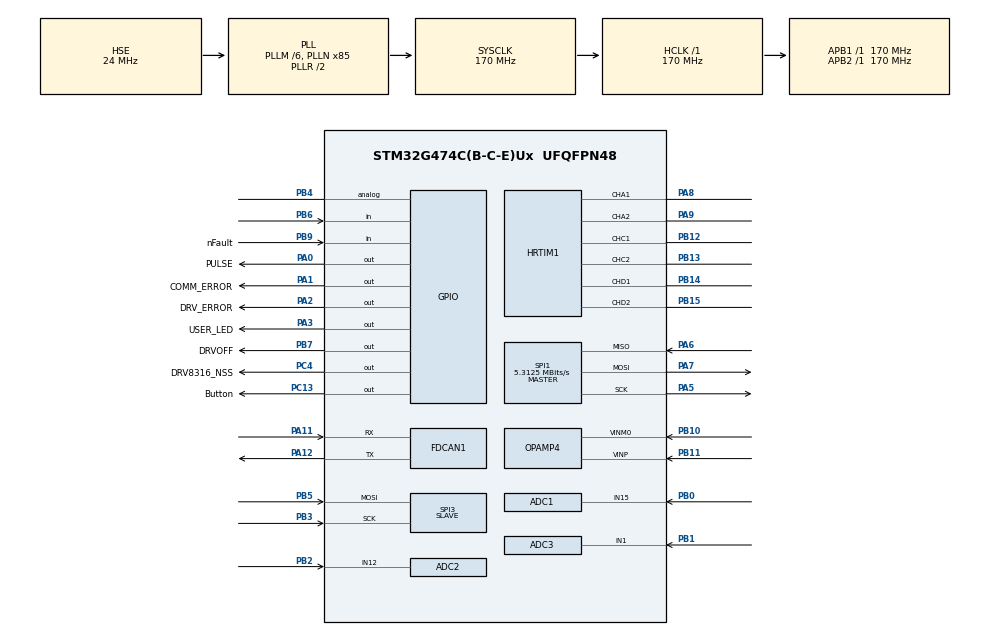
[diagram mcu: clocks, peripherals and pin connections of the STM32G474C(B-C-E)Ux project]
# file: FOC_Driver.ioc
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ADC1.DMAContinuousRequests=DISABLE
ADC1.EnableInjectedConversion=ENABLE
ADC1.EnableInjectedOversampling=DISABLE
ADC1.EnableRegularConversion=DISABLE
ADC1.ExternalTrigInjecConv=ADC_EXTERNALTRIGINJEC_HRTIM_TRG2
ADC1.InjNumberOfConversion=1
ADC1.InjectedChannel-18\#ChannelInjectedConversion=ADC_CHANNEL_15
ADC1.InjectedConvMode=None
ADC1.InjectedOffsetNumber-18\#ChannelInjectedConversion=ADC_OFFSET_NONE
ADC1.InjectedRank-18\#ChannelInjectedConversion=1
ADC1.InjectedSamplingTime-18\#ChannelInjectedConversion=ADC_SAMPLETIME_24CYCLES_5
ADC1.Overrun=ADC_OVR_DATA_OVERWRITTEN
ADC1.injectedQueueMode=DISABLE
ADC1.master=1
ADC2.ClockPrescaler=ADC_CLOCK_SYNC_PCLK_DIV4
ADC2.ContinuousConvMode=DISABLE
ADC2.DMAContinuousRequests=DISABLE
ADC2.EnableInjectedConversion=ENABLE
ADC2.EnableInjectedOversampling=DISABLE
ADC2.EnableRegularConversion=DISABLE
ADC2.ExternalTrigInjecConv=ADC_EXTERNALTRIGINJEC_HRTIM_TRG2
ADC2.InjNumberOfConversion=1
ADC2.InjectedChannel-6\#ChannelInjectedConversion=ADC_CHANNEL_12
ADC2.InjectedOffsetNumber-6\#ChannelInjectedConversion=ADC_OFFSET_NONE
ADC2.InjectedRank-6\#ChannelInjectedConversion=1
ADC2.InjectedSamplingTime-6\#ChannelInjectedConversion=ADC_SAMPLETIME_24CYCLES_5
ADC2.Overrun=ADC_OVR_DATA_OVERWRITTEN
ADC2.OversamplingMode=DISABLE
ADC3.DMAContinuousRequests=DISABLE
ADC3.EnableInjectedConversion=ENABLE
ADC3.EnableInjectedOversampling=DISABLE
ADC3.EnableRegularConversion=DISABLE
ADC3.ExternalTrigInjecConv=ADC_EXTERNALTRIGINJEC_HRTIM_TRG2
ADC3.InjNumberOfConversion=1
ADC3.InjectedChannel-5\#ChannelInjectedConversion=ADC_CHANNEL_1
ADC3.InjectedOffsetNumber-5\#ChannelInjectedConversion=ADC_OFFSET_NONE
ADC3.InjectedRank-5\#ChannelInjectedConversion=1
ADC3.InjectedSamplingTime-5\#ChannelInjectedConversion=ADC_SAMPLETIME_24CYCLES_5
ADC3.Overrun=ADC_OVR_DATA_OVERWRITTEN
ADC3.Rank1_Channel=ADC_CHANNEL_1
ADC3.master=1
ADC5.Channel-0\#ChannelRegularConversion=ADC_CHANNEL_VREFINT
ADC5.Channel-1\#ChannelRegularConversion=ADC_CHANNEL_TEMPSENSOR_ADC5
ADC5.ClockPrescaler=ADC_CLOCK_SYNC_PCLK_DIV4
ADC5.ContinuousConvMode=ENABLE
ADC5.DMAContinuousRequests=ENABLE
ADC5.NbrOfConversion=2
ADC5.NbrOfConversionFlag=1
ADC5.OffsetNumber-0\#ChannelRegularConversion=ADC_OFFSET_NONE
ADC5.OffsetNumber-1\#ChannelRegularConversion=ADC_OFFSET_NONE
ADC5.Overrun=ADC_OVR_DATA_OVERWRITTEN
ADC5.OversamplingMode=DISABLE
ADC5.Rank-0\#ChannelRegularConversion=1
ADC5.Rank-1\#ChannelRegularConversion=2
ADC5.SamplingTime-0\#ChannelRegularConversion=ADC_SAMPLETIME_640CYCLES_5
ADC5.SamplingTime-1\#ChannelRegularConversion=ADC_SAMPLETIME_640CYCLES_5
Dma.ADC5.2.Direction=DMA_PERIPH_TO_MEMORY
Dma.ADC5.2.EventEnable=DISABLE
Dma.ADC5.2.Instance=DMA1_Channel1
Dma.ADC5.2.MemDataAlignment=DMA_MDATAALIGN_HALFWORD
Dma.ADC5.2.MemInc=DMA_MINC_ENABLE
Dma.ADC5.2.Mode=DMA_CIRCULAR
Dma.ADC5.2.PeriphDataAlignment=DMA_PDATAALIGN_HALFWORD
Dma.ADC5.2.PeriphInc=DMA_PINC_DISABLE
Dma.ADC5.2.Polarity=HAL_DMAMUX_REQ_GEN_RISING
Dma.ADC5.2.Priority=DMA_PRIORITY_LOW
Dma.ADC5.2.RequestNumber=1
Dma.ADC5.2.SignalID=NONE
Dma.ADC5.2.SyncEnable=DISABLE
Dma.ADC5.2.SyncPolarity=HAL_DMAMUX_SYNC_NO_EVENT
Dma.ADC5.2.SyncRequestNumber=1
Dma.ADC5.2.SyncSignalID=NONE
Dma.Request0=SPI1_RX
Dma.Request1=SPI1_TX
Dma.Request2=ADC5
Dma.Request3=SPI3_RX
Dma.SPI1_RX.0.Direction=DMA_PERIPH_TO_MEMORY
Dma.SPI1_RX.0.EventEnable=DISABLE
Dma.SPI1_RX.0.Instance=DMA2_Channel5
Dma.SPI1_RX.0.MemDataAlignment=DMA_MDATAALIGN_HALFWORD
Dma.SPI1_RX.0.MemInc=DMA_MINC_ENABLE
Dma.SPI1_RX.0.Mode=DMA_NORMAL
Dma.SPI1_RX.0.PeriphDataAlignment=DMA_PDATAALIGN_HALFWORD
Dma.SPI1_RX.0.PeriphInc=DMA_PINC_DISABLE
Dma.SPI1_RX.0.Polarity=HAL_DMAMUX_REQ_GEN_RISING
Dma.SPI1_RX.0.Priority=DMA_PRIORITY_LOW
Dma.SPI1_RX.0.RequestNumber=1
Dma.SPI1_RX.0.SignalID=NONE
Dma.SPI1_RX.0.SyncEnable=DISABLE
Dma.SPI1_RX.0.SyncPolarity=HAL_DMAMUX_SYNC_NO_EVENT
Dma.SPI1_RX.0.SyncRequestNumber=1
Dma.SPI1_RX.0.SyncSignalID=NONE
Dma.SPI1_TX.1.Direction=DMA_MEMORY_TO_PERIPH
Dma.SPI1_TX.1.EventEnable=DISABLE
Dma.SPI1_TX.1.Instance=DMA2_Channel4
Dma.SPI1_TX.1.MemDataAlignment=DMA_MDATAALIGN_HALFWORD
Dma.SPI1_TX.1.MemInc=DMA_MINC_ENABLE
Dma.SPI1_TX.1.Mode=DMA_NORMAL
Dma.SPI1_TX.1.PeriphDataAlignment=DMA_PDATAALIGN_HALFWORD
Dma.SPI1_TX.1.PeriphInc=DMA_PINC_DISABLE
Dma.SPI1_TX.1.Polarity=HAL_DMAMUX_REQ_GEN_RISING
Dma.SPI1_TX.1.Priority=DMA_PRIORITY_LOW
Dma.SPI1_TX.1.RequestNumber=1
Dma.SPI1_TX.1.SignalID=NONE
Dma.SPI1_TX.1.SyncEnable=DISABLE
Dma.SPI1_TX.1.SyncPolarity=HAL_DMAMUX_SYNC_NO_EVENT
Dma.SPI1_TX.1.SyncRequestNumber=1
Dma.SPI1_TX.1.SyncSignalID=NONE
Dma.SPI3_RX.3.Direction=DMA_PERIPH_TO_MEMORY
Dma.SPI3_RX.3.EventEnable=DISABLE
Dma.SPI3_RX.3.Instance=DMA2_Channel2
Dma.SPI3_RX.3.MemDataAlignment=DMA_MDATAALIGN_HALFWORD
Dma.SPI3_RX.3.MemInc=DMA_MINC_ENABLE
Dma.SPI3_RX.3.Mode=DMA_NORMAL
Dma.SPI3_RX.3.PeriphDataAlignment=DMA_PDATAALIGN_HALFWORD
Dma.SPI3_RX.3.PeriphInc=DMA_PINC_DISABLE
Dma.SPI3_RX.3.Polarity=HAL_DMAMUX_REQ_GEN_RISING
Dma.SPI3_RX.3.Priority=DMA_PRIORITY_LOW
Dma.SPI3_RX.3.RequestNumber=1
Dma.SPI3_RX.3.SignalID=NONE
Dma.SPI3_RX.3.SyncEnable=DISABLE
Dma.SPI3_RX.3.SyncPolarity=HAL_DMAMUX_SYNC_NO_EVENT
Dma.SPI3_RX.3.SyncRequestNumber=1
Dma.SPI3_RX.3.SyncSignalID=NONE
FDCAN1.AutoRetransmission=DISABLE
FDCAN1.CalculateBaudRateNominal=999999
FDCAN1.CalculateTimeBitNominal=1000
FDCAN1.CalculateTimeQuantumNominal=11.764705882352942
FDCAN1.ClockDivider=FDCAN_CLOCK_DIV1
FDCAN1.DataPrescaler=2
FDCAN1.DataSyncJumpWidth=4
FDCAN1.DataTimeSeg1=12
FDCAN1.DataTimeSeg2=4
FDCAN1.ExtFiltersNbr=1
FDCAN1.FrameFormat=FDCAN_FRAME_FD_BRS
FDCAN1.NominalPrescaler=2
FDCAN1.NominalSyncJumpWidth=8
FDCAN1.NominalTimeSeg1=67
FDCAN1.NominalTimeSeg2=17
FDCAN1.StdFiltersNbr=1
FDCAN1.TxFifoQueueMode=FDCAN_TX_FIFO_OPERATION
HRTIM1.ADCTrigger2_Source1=HRTIM_ADCTRIGGEREVENT24_MASTER_CMP1
HRTIM1.ADCTrigger_Id1=__NULL
HRTIM1.ADCTrigger_Id2=HRTIM_ADCTRIGGER_2
HRTIM1.BurstDMAconfig-MasterTimer=__NULL
HRTIM1.BurstDMAconfig-Output_TA1TA2=HRTIM_TIMERINDEX_TIMER_A
HRTIM1.BurstDMAconfig-Output_TC1TC2=HRTIM_TIMERINDEX_TIMER_C
HRTIM1.BurstDMAconfig-Output_TD1TD2=HRTIM_TIMERINDEX_TIMER_D
HRTIM1.CompareUnit1-MasterTimer=HRTIM_COMPAREUNIT_1
HRTIM1.CompareUnit1-Output_TA1TA2=HRTIM_COMPAREUNIT_1
HRTIM1.CompareUnit1-Output_TC1TC2=HRTIM_COMPAREUNIT_1
HRTIM1.CompareUnit1-Output_TD1TD2=HRTIM_COMPAREUNIT_1
HRTIM1.CompareUnit2-MasterTimer=__NULL
HRTIM1.CompareUnit2-Output_TA1TA2=HRTIM_COMPAREUNIT_2
HRTIM1.CompareValue1-Output_TA1TA2=FULL_DUTY*0.2
HRTIM1.CompareValue1-Output_TC1TC2=FULL_DUTY*0.2
HRTIM1.CompareValue1-Output_TD1TD2=FULL_DUTY*0.2
HRTIM1.CompareValue2-Output_TA1TA2=200
HRTIM1.DACSynchro-MasterTimer=HRTIM_DACSYNC_NONE
HRTIM1.DeadTimeInsertion-Output_TA1TA2=HRTIM_TIMDEADTIMEINSERTION_ENABLED
HRTIM1.DeadTimeInsertion-Output_TC1TC2=HRTIM_TIMDEADTIMEINSERTION_ENABLED
HRTIM1.DeadTimeInsertion-Output_TD1TD2=HRTIM_TIMDEADTIMEINSERTION_ENABLED
HRTIM1.DualChannelDacEnableFake_TA-Output_TA1TA2=HRTIM_TIMER_DCDE_DISABLED
HRTIM1.FallingValue-Output_TA1TA2=DEAD_TIME
HRTIM1.FallingValue-Output_TC1TC2=DEAD_TIME
HRTIM1.FallingValue-Output_TD1TD2=DEAD_TIME
HRTIM1.InterleavedMode-MasterTimer=HRTIM_INTERLEAVED_MODE_DUAL
HRTIM1.InterleavedMode-Output_TA1TA2=HRTIM_INTERLEAVED_MODE_DISABLED
HRTIM1.InterruptRequests1_Master=HRTIM_MASTER_IT_MREP
HRTIM1.ModeTimeBase-MasterTimer=HRTIM_MODE_CONTINUOUS
HRTIM1.ModeTimeBase-Output_TA1TA2=HRTIM_MODE_CONTINUOUS
HRTIM1.ModeTimeBase-Output_TD1TD2=HRTIM_MODE_CONTINUOUS
HRTIM1.NumberADCTriggerSource2=1
HRTIM1.NumberDMARequests_TA=0
HRTIM1.NumberDMARequests_TC=0
HRTIM1.NumberDMARequests_TD=0
HRTIM1.NumberInterruptRequests-Output_TA1TA2=0
HRTIM1.NumberInterruptRequests_Master-MasterTimer=1
HRTIM1.NumberRegisters_BURSTDMA-Output_TA1TA2=0
HRTIM1.NumberRegisters_BURSTDMA-Output_TC1TC2=0
HRTIM1.NumberRegisters_BURSTDMA-Output_TD1TD2=0
HRTIM1.NumberResetSource1-Output_TA1TA2=0
HRTIM1.NumberResetSource1-Output_TC1TC2=0
HRTIM1.NumberResetSource1-Output_TD1TD2=1
HRTIM1.NumberResetTrigger-Output_TA1TA2=1
HRTIM1.NumberResetTrigger-Output_TC1TC2=1
HRTIM1.NumberResetTrigger-Output_TD1TD2=1
HRTIM1.NumberSetSource1-Output_TA1TA2=1
HRTIM1.NumberSetSource1-Output_TC1TC2=1
HRTIM1.NumberSetSource1-Output_TD1TD2=1
HRTIM1.NumberSetSource2_TA=0
HRTIM1.NumberUpdateTrigger-Output_TA1TA2=0
HRTIM1.ORingUpdateSource_ADCTrigger2=HRTIM_ADCTRIGGERUPDATE_MASTER
HRTIM1.Periode_MASTER=FULL_DUTY
HRTIM1.Periode_TA=FULL_DUTY
HRTIM1.Periode_TC=FULL_DUTY
HRTIM1.Periode_TD=FULL_DUTY
HRTIM1.PreloadEnable-MasterTimer=HRTIM_PRELOAD_ENABLED
HRTIM1.PreloadEnable-Output_TA1TA2=HRTIM_PRELOAD_ENABLED
HRTIM1.PreloadEnable-Output_TC1TC2=HRTIM_PRELOAD_ENABLED
HRTIM1.PreloadEnable-Output_TD1TD2=HRTIM_PRELOAD_ENABLED
HRTIM1.PrescalerDead-Output_TA1TA2=HRTIM_TIMDEADTIME_PRESCALERRATIO_MUL2
HRTIM1.PrescalerDead-Output_TC1TC2=HRTIM_TIMDEADTIME_PRESCALERRATIO_MUL2
HRTIM1.PrescalerDead-Output_TD1TD2=HRTIM_TIMDEADTIME_PRESCALERRATIO_MUL2
HRTIM1.PrescalerRatio_MASTER=HRTIM_PRESCALERRATIO_MUL4
HRTIM1.PrescalerRatio_TA=HRTIM_PRESCALERRATIO_MUL8
HRTIM1.PrescalerRatio_TC=HRTIM_PRESCALERRATIO_MUL8
HRTIM1.PrescalerRatio_TD=HRTIM_PRESCALERRATIO_MUL8
HRTIM1.ReSyncUpdate-Output_TA1TA2=HRTIM_TIMERESYNC_UPDATE_UNCONDITIONAL
HRTIM1.ReSyncUpdate-Output_TD1TD2=HRTIM_TIMERESYNC_UPDATE_UNCONDITIONAL
HRTIM1.RepetitionCounter-MasterTimer=0
HRTIM1.RepetitionCounter-Output_TA1TA2=0
HRTIM1.RepetitionCounter-Output_TD1TD2=0
HRTIM1.RepetitionUpdate-MasterTimer=HRTIM_UPDATEONREPETITION_ENABLED
HRTIM1.RepetitionUpdate-Output_TA1TA2=HRTIM_UPDATEONREPETITION_DISABLED
HRTIM1.RepetitionUpdate-Output_TD1TD2=HRTIM_UPDATEONREPETITION_DISABLED
HRTIM1.ResetOnSync-MasterTimer=HRTIM_SYNCRESET_DISABLED
HRTIM1.ResetOnSync-Output_TA1TA2=HRTIM_SYNCRESET_DISABLED
HRTIM1.ResetOnSync-Output_TD1TD2=HRTIM_SYNCRESET_DISABLED
HRTIM1.ResetOutput1_Source1-Output_TD1TD2=HRTIM_OUTPUTRESET_NONE
HRTIM1.ResetTrigger1-Output_TA1TA2=HRTIM_TIMRESETTRIGGER_MASTER_PER
HRTIM1.ResetTrigger1-Output_TC1TC2=HRTIM_TIMRESETTRIGGER_MASTER_PER
HRTIM1.ResetTrigger1-Output_TD1TD2=HRTIM_TIMRESETTRIGGER_MASTER_PER
HRTIM1.ResetUpdate-Output_TA1TA2=HRTIM_TIMUPDATEONRESET_ENABLED
HRTIM1.ResetUpdate-Output_TC1TC2=HRTIM_TIMUPDATEONRESET_ENABLED
HRTIM1.ResetUpdate-Output_TD1TD2=HRTIM_TIMUPDATEONRESET_ENABLED
HRTIM1.RisingValue-Output_TA1TA2=DEAD_TIME
HRTIM1.RisingValue-Output_TC1TC2=DEAD_TIME
HRTIM1.RisingValue-Output_TD1TD2=DEAD_TIME
HRTIM1.SetOutput1_Source1-Output_TA1TA2=HRTIM_OUTPUTSET_TIMCMP1
HRTIM1.SetOutput1_Source1-Output_TC1TC2=HRTIM_OUTPUTSET_TIMCMP1
HRTIM1.SetOutput1_Source1-Output_TD1TD2=HRTIM_OUTPUTSET_TIMCMP1
HRTIM1.StartOnSync-MasterTimer=HRTIM_SYNCSTART_DISABLED
HRTIM1.StartOnSync-Output_TA1TA2=HRTIM_SYNCSTART_DISABLED
HRTIM1.StartOnSync-Output_TD1TD2=HRTIM_SYNCSTART_DISABLED
HRTIM1.SyncOptions=HRTIM_SYNCOPTION_NONE
HRTIM1.UpDownMode-Output_TA1TA2=HRTIM_TIMERUPDOWNMODE_UPDOWN
HRTIM1.UpDownMode-Output_TC1TC2=HRTIM_TIMERUPDOWNMODE_UPDOWN
HRTIM1.UpDownMode-Output_TD1TD2=HRTIM_TIMERUPDOWNMODE_UPDOWN
HRTIM1.rom_TA=HRTIM_TIM_ROM_VALLEY
HRTIM1.rom_TC=HRTIM_TIM_ROM_VALLEY
HRTIM1.rom_TD=HRTIM_TIM_ROM_VALLEY
Mcu.Family=STM32G4
Mcu.Name=STM32G474C(B-C-E)Ux
Mcu.Package=UFQFPN48
Mcu.UserConstants=DEAD_TIME,0;FULL_DUTY,13600;ENCODER_SCALER,17000;VELOCITY_CONTROL,34000
NVIC.ADC1_2_IRQn=true\:1\:0\:true\:false\:true\:true\:true\:true
NVIC.DMA1_Channel1_IRQn=true\:0\:0\:false\:false\:true\:false\:true\:true
NVIC.DMA2_Channel2_IRQn=true\:0\:0\:false\:false\:true\:false\:true\:true
NVIC.DMA2_Channel4_IRQn=true\:3\:0\:true\:false\:true\:false\:true\:true
NVIC.DMA2_Channel5_IRQn=true\:3\:0\:true\:false\:true\:false\:true\:true
NVIC.FDCAN1_IT0_IRQn=true\:13\:0\:true\:false\:true\:true\:true\:true
NVIC.FDCAN1_IT1_IRQn=true\:13\:0\:true\:false\:true\:true\:true\:true
NVIC.HRTIM1_Master_IRQn=true\:0\:0\:true\:false\:true\:true\:true\:true
NVIC.PriorityGroup=NVIC_PRIORITYGROUP_4
NVIC.TIM1_TRG_COM_TIM17_IRQn=true\:9\:0\:true\:false\:true\:true\:true\:true
NVIC.TIM1_UP_TIM16_IRQn=true\:15\:0\:true\:false\:true\:true\:true\:true
NVIC.TIM6_DAC_IRQn=true\:7\:0\:true\:false\:true\:true\:true\:true
NVIC.TIM7_DAC_IRQn=true\:8\:0\:true\:false\:true\:true\:true\:true
PA0.GPIO_Label=PULSE
PA0.Signal=GPIO_Output
PA1.GPIO_Label=COMM_ERROR
PA1.Signal=GPIO_Output
PA11.Mode=FDCAN_Activate
PA11.Signal=FDCAN1_RX
PA12.Mode=FDCAN_Activate
PA12.Signal=FDCAN1_TX
PA13.Mode=Serial_Wire
PA13.Signal=SYS_JTMS-SWDIO
PA14.Mode=Serial_Wire
PA14.Signal=SYS_JTCK-SWCLK
PA2.GPIO_Label=DRV_ERROR
PA2.Signal=GPIO_Output
PA3.GPIO_Label=USER_LED
PA3.Signal=GPIO_Output
PA5.Mode=Full_Duplex_Master
PA5.Signal=SPI1_SCK
PA6.Mode=Full_Duplex_Master
PA6.Signal=SPI1_MISO
PA7.Mode=Full_Duplex_Master
PA7.Signal=SPI1_MOSI
PA8.Mode=Output_TA1TA2
PA8.Signal=HRTIM1_CHA1
PA9.Mode=Output_TA1TA2
PA9.Signal=HRTIM1_CHA2
PB0.Mode=IN15-Single-Ended
PB0.Signal=ADC1_IN15
PB1.Mode=IN1-Single-Ended
PB1.Signal=ADC3_IN1
PB10.Mode=standalone Internally connected_IO
PB10.Signal=OPAMP4_VINM0
PB11.Mode=standalone Internally connected_IO
PB11.Signal=OPAMP4_VINP
PB12.Mode=Output_TC1TC2
PB12.Signal=HRTIM1_CHC1
PB13.Mode=Output_TC1TC2
PB13.Signal=HRTIM1_CHC2
PB14.Mode=Output_TD1TD2
PB14.Signal=HRTIM1_CHD1
PB15.Mode=Output_TD1TD2
PB15.Signal=HRTIM1_CHD2
PB2.Mode=IN12-Single-Ended
PB2.Signal=ADC2_IN12
PB3.Mode=RX_Only_Simplex_Unidirect_Slave
PB3.Signal=SPI3_SCK
PB4.Signal=GPIO_Analog
PB5.Mode=RX_Only_Simplex_Unidirect_Slave
PB5.Signal=SPI3_MOSI
PB6.Signal=GPIO_Input
PB7.GPIO_Label=DRVOFF
PB7.Signal=GPIO_Output
PB9.GPIO_Label=nFault
PB9.Signal=GPIO_Input
PC13.GPIO_Label=Button
PC13.Signal=GPIO_Output
PC4.GPIO_Label=DRV8316_NSS
PC4.Signal=GPIO_Output
PF0-OSC_IN.Mode=HSE-External-Oscillator
PF0-OSC_IN.Signal=RCC_OSC_IN
PF1-OSC_OUT.Mode=HSE-External-Oscillator
PF1-OSC_OUT.Signal=RCC_OSC_OUT
ProjectManager.HeapSize=0x200
ProjectManager.StackSize=0x400
ProjectManager.TargetToolchain=CMake
RCC.ADC12Freq_Value=170000000
RCC.ADC345Freq_Value=170000000
RCC.AHBFreq_Value=170000000
RCC.APB1Freq_Value=170000000
RCC.APB1TimFreq_Value=170000000
RCC.APB2Freq_Value=170000000
RCC.APB2TimFreq_Value=170000000
RCC.CortexFreq_Value=170000000
RCC.EXTERNAL_CLOCK_VALUE=12288000
RCC.HCLKFreq_Value=170000000
RCC.HSE_VALUE=24000000
RCC.HSI48_VALUE=48000000
RCC.HSI_VALUE=16000000
RCC.LSE_VALUE=32768
RCC.PLLM=RCC_PLLM_DIV6
RCC.PLLN=85
RCC.PLLSourceVirtual=RCC_PLLSOURCE_HSE
RCC.SYSCLKFreq_VALUE=170000000
RCC.SYSCLKSource=RCC_SYSCLKSOURCE_PLLCLK
RCC.USBFreq_Value=170000000
RCC.VCOOutputFreq_Value=340000000
SPI1.BaudRatePrescaler=SPI_BAUDRATEPRESCALER_32
SPI1.CLKPhase=SPI_PHASE_2EDGE
SPI1.CLKPolarity=SPI_POLARITY_LOW
SPI1.CalculateBaudRate=5.3125 MBits/s
SPI1.DataSize=SPI_DATASIZE_16BIT
SPI1.Direction=SPI_DIRECTION_2LINES
SPI1.Mode=SPI_MODE_MASTER
SPI1.VirtualType=VM_MASTER
SPI3.DataSize=SPI_DATASIZE_16BIT
SPI3.Direction=SPI_DIRECTION_2LINES_RXONLY
SPI3.Mode=SPI_MODE_SLAVE
SPI3.VirtualType=VM_SLAVE
TIM16.PeriodNoDither=10000-1
TIM16.Prescaler=17000-1
TIM17.PeriodNoDither=1000-1
TIM17.Prescaler=170-1
TIM2.Prescaler=0
TIM6.PeriodNoDither=ENCODER_SCALER-1
TIM6.Prescaler=0
TIM7.PeriodNoDither=VELOCITY_CONTROL-1
TIM7.Prescaler=0
VP_ADC1_Vref_Input.Mode=IN-Vrefint
VP_ADC5_OPAMP_INTERNAL4.Mode=IN-OPAMP4
VP_ADC5_TempSens_Input.Mode=IN-TempSens
VP_ADC5_Vref_Input.Mode=IN-Vrefint
VP_FMAC_VS_FMAC.Mode=FMAC_Activate
VP_HRTIM1_VS_hrtimMasterTimerNoOutput.Mode=MasterTimer
VP_SYS_VS_DBSignals.Mode=DisableDeadBatterySignals
VP_TIM16_VS_ClockSourceINT.Mode=Enable_Timer
VP_TIM17_VS_ClockSourceINT.Mode=Enable_Timer
VP_TIM2_VS_ClockSourceINT.Mode=Internal
VP_TIM6_VS_ClockSourceINT.Mode=Enable_Timer
VP_TIM7_VS_ClockSourceINT.Mode=Enable_Timer
board=custom

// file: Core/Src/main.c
/* USER CODE BEGIN Header */
/**
 ******************************************************************************
 * @file           : main.c
 * @brief          : Main program body
 ******************************************************************************
 * @attention
 *
 * Copyright (c) 2025 STMicroelectronics.
 * All rights reserved.
 *
 * This software is licensed under terms that can be found in the LICENSE file
 * in the root directory of this software component.
 * If no LICENSE file comes with this software, it is provided AS-IS.
 *
 ******************************************************************************
 */
/* USER CODE END Header */
#include "main.h"
#include "adc.h"
#include "dma.h"
#include "fdcan.h"
#include "fmac.h"
#include "hrtim.h"
#include "opamp.h"
#include "spi.h"
#include "tim.h"
#include "gpio.h"

/* USER CODE BEGIN Includes */
#include "error_handler.hpp"
/* USER CODE END Includes */

void SystemClock_Config(void);

int main(void)
{

  /* MCU Configuration--------------------------------------------------------*/

  /* Reset of all peripherals, Initializes the Flash interface and the Systick. */
  HAL_Init();

  /* Configure the system clock */
  SystemClock_Config();

  /* Initialize all configured peripherals */
  MX_GPIO_Init();
  MX_DMA_Init();
  MX_SPI1_Init();
  MX_ADC1_Init();
  MX_ADC2_Init();
  MX_ADC3_Init();
  MX_HRTIM1_Init();
  MX_TIM2_Init();
  MX_FMAC_Init();
  MX_TIM6_Init();
  MX_FDCAN1_Init();
  MX_ADC5_Init();
  MX_OPAMP4_Init();
  MX_TIM7_Init();
  MX_TIM16_Init();
  MX_TIM17_Init();
  MX_SPI3_Init();
  /* USER CODE BEGIN 2 */
  main_cpp();
  /* USER CODE END 2 */

  /* Infinite loop */
  while (1)
  {

  }
}

void SystemClock_Config(void)
{
  RCC_OscInitTypeDef RCC_OscInitStruct = {0};
  RCC_ClkInitTypeDef RCC_ClkInitStruct = {0};

  /** Configure the main internal regulator output voltage
  */
  HAL_PWREx_ControlVoltageScaling(PWR_REGULATOR_VOLTAGE_SCALE1_BOOST);

  /** Initializes the RCC Oscillators according to the specified parameters
  * in the RCC_OscInitTypeDef structure.
  */
  RCC_OscInitStruct.OscillatorType = RCC_OSCILLATORTYPE_HSE;
  RCC_OscInitStruct.HSEState = RCC_HSE_ON;
  RCC_OscInitStruct.PLL.PLLState = RCC_PLL_ON;
  RCC_OscInitStruct.PLL.PLLSource = RCC_PLLSOURCE_HSE;
  RCC_OscInitStruct.PLL.PLLM = RCC_PLLM_DIV6;
  RCC_OscInitStruct.PLL.PLLN = 85;
  RCC_OscInitStruct.PLL.PLLP = RCC_PLLP_DIV2;
  RCC_OscInitStruct.PLL.PLLQ = RCC_PLLQ_DIV2;
  RCC_OscInitStruct.PLL.PLLR = RCC_PLLR_DIV2;
  if (HAL_RCC_OscConfig(&RCC_OscInitStruct) != HAL_OK)
  {
    Error_Handler();
  }

  /** Initializes the CPU, AHB and APB buses clocks
  */
  RCC_ClkInitStruct.ClockType = RCC_CLOCKTYPE_HCLK|RCC_CLOCKTYPE_SYSCLK
                              |RCC_CLOCKTYPE_PCLK1|RCC_CLOCKTYPE_PCLK2;
  RCC_ClkInitStruct.SYSCLKSource = RCC_SYSCLKSOURCE_PLLCLK;
  RCC_ClkInitStruct.AHBCLKDivider = RCC_SYSCLK_DIV1;
  RCC_ClkInitStruct.APB1CLKDivider = RCC_HCLK_DIV1;
  RCC_ClkInitStruct.APB2CLKDivider = RCC_HCLK_DIV1;

  if (HAL_RCC_ClockConfig(&RCC_ClkInitStruct, FLASH_LATENCY_4) != HAL_OK)
  {
    Error_Handler();
  }
}

void Error_Handler(void)
{
  /* USER CODE BEGIN Error_Handler_Debug */
  /* User can add his own implementation to report the HAL error return state */

  while (1) {
    _Error_Handler();
  }
  /* USER CODE END Error_Handler_Debug */
}
#ifdef USE_FULL_ASSERT
/**
  * @brief  Reports the name of the source file and the source line number
  *         where the assert_param error has occurred.
  * @param  file: pointer to the source file name
  * @param  line: assert_param error line source number
  * @retval None
  */
void assert_failed(uint8_t *file, uint32_t line)
{
  /* USER CODE BEGIN 6 */
  //   /* User can add his own implementation to report the file name and line number,
  //      ex: printf("Wrong parameters value: file %s on line %d\r\n", file, line) */
  /* USER CODE END 6 */
}
#endif /* USE_FULL_ASSERT */
